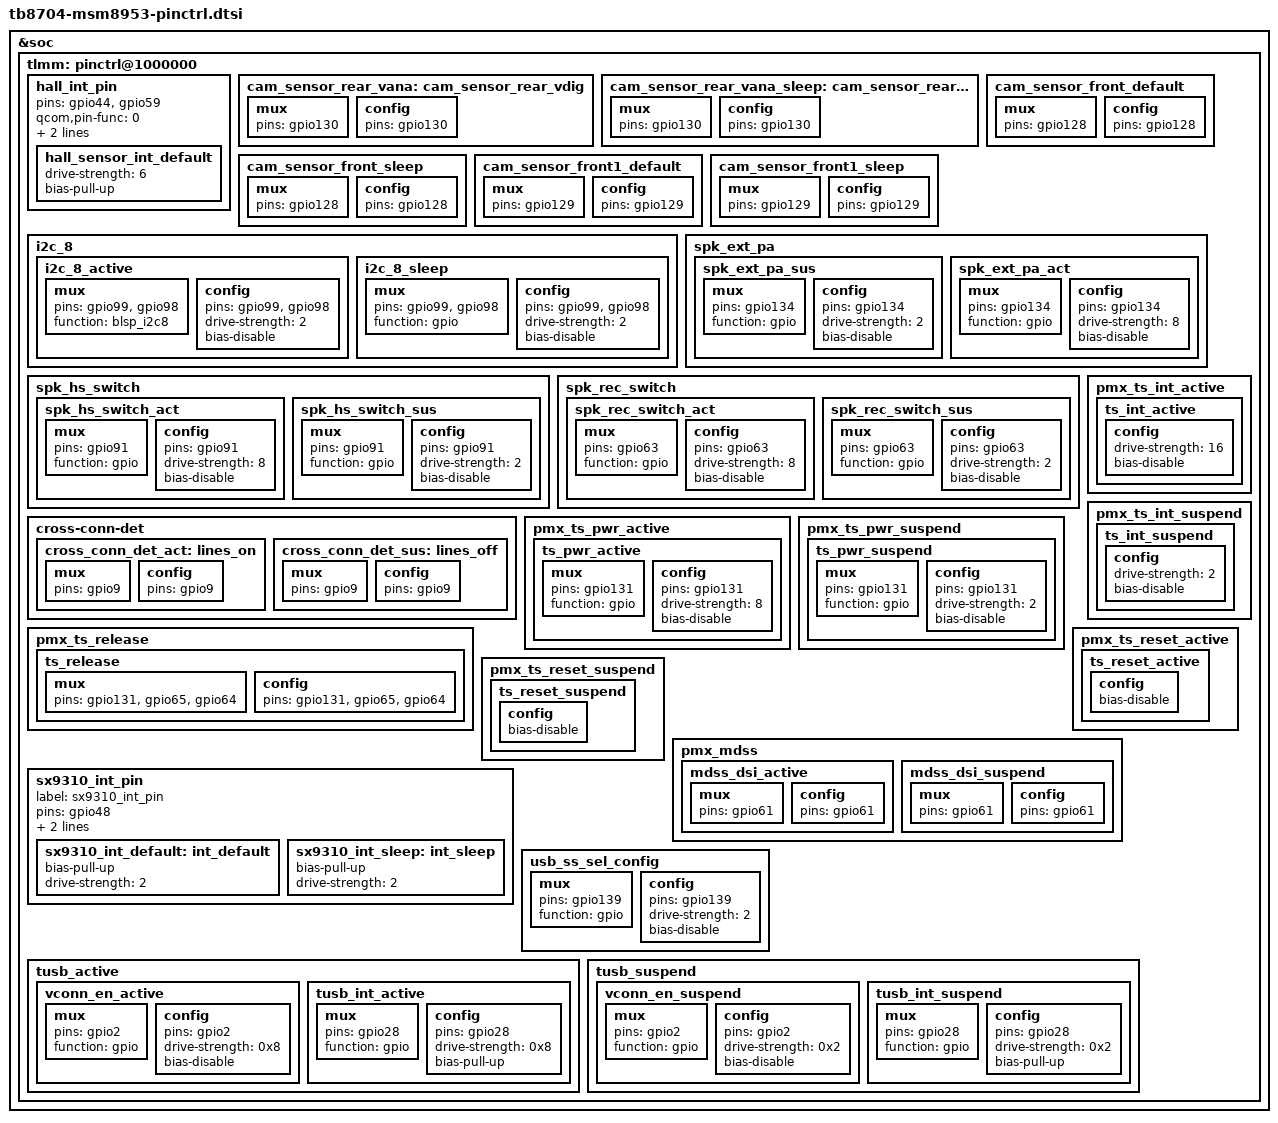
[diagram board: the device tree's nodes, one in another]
/*
 * Copyright (c) 2015-2016, The Linux Foundation. All rights reserved.
 *
 * This program is free software; you can redistribute it and/or modify
 * it under the terms of the GNU General Public License version 2 and
 * only version 2 as published by the Free Software Foundation.
 *
 * This program is distributed in the hope that it will be useful,
 * but WITHOUT ANY WARRANTY; without even the implied warranty of
 * MERCHANTABILITY or FITNESS FOR A PARTICULAR PURPOSE.  See the
 * GNU General Public License for more details.
 */

&soc {
	tlmm: pinctrl@1000000 {
		hall_int_pin {
			pins = "gpio44", "gpio59";
			qcom,pin-func = <0>;
			qcom,num-grp-pins = <2>;
			label = "hall_irq";
			hall_sensor_int_default: hall_sensor_int_default {
				drive-strength = <6>;
				bias-pull-up;
			};
		};

		cam_sensor_rear_vana: cam_sensor_rear_vdig {
			/* VDIG */
			mux {
				pins = "gpio130";
			};

			config {
				pins = "gpio130";
			};
		};

		cam_sensor_rear_vana_sleep: cam_sensor_rear_vdig_sleep {
			/* VDIG */
			mux {
				pins = "gpio130";
			};

			config {
				pins = "gpio130";
			};
		};


		cam_sensor_front_default: cam_sensor_front_default {
			/* RESET, STANDBY */
			mux {
				pins = "gpio128";
			};

			config {
				pins = "gpio128";
			};
		};

		cam_sensor_front_sleep: cam_sensor_front_sleep {
			/* RESET, STANDBY */
			mux {
				pins = "gpio128";
			};

			config {
				pins = "gpio128";
			};
		};


		cam_sensor_front1_default: cam_sensor_front1_default {
			/* RESET, STANDBY */
			mux {
				pins = "gpio129";
			};

			config {
				pins = "gpio129";
			};
		};

		cam_sensor_front1_sleep: cam_sensor_front1_sleep {
			/* RESET, STANDBY */
			mux {
				pins = "gpio129";
			};

			config {
				pins = "gpio129";
			};
		};

		i2c_8 {
			i2c_8_active: i2c_8_active {
				/* active state */
				mux {
					pins = "gpio99", "gpio98";
					function = "blsp_i2c8";
				};

				config {
					pins = "gpio99", "gpio98";
					drive-strength = <2>;
					bias-disable;
				};
			};

			i2c_8_sleep: i2c_8_sleep {
				/* suspended state */
				mux {
					pins = "gpio99", "gpio98";
					function = "gpio";
				};

				config {
					pins = "gpio99", "gpio98";
					drive-strength = <2>;
					bias-disable;
				};
			};
		};

		spk_ext_pa {
			spk_ext_pa_sus: spk_ext_pa_sus {
				mux {
					pins = "gpio134";
					function = "gpio";
				};
				config {
				    pins = "gpio134";
				    drive-strength = <2>;
				    //output-low;
				    //bias-pull-down;
				    bias-disable;
				};
			};
			spk_ext_pa_act: spk_ext_pa_act {
				mux {
					pins = "gpio134";
					function = "gpio";
				};
				config {
				    pins = "gpio134";
				    drive-strength = <8>;
				    bias-disable;
				};
			};
		};

		spk_hs_switch {
			spk_hs_switch_act: spk_hs_switch_act {
				mux {
					pins = "gpio91";
					function = "gpio";
				};
				config {
				    pins = "gpio91";
				    drive-strength = <8>;
				    bias-disable;
				    //output-high;
				};
			};
			spk_hs_switch_sus: spk_hs_switch_sus {
				mux {
					pins = "gpio91";
					function = "gpio";
				};
				config {
					pins = "gpio91";
					drive-strength = <2>;
					bias-disable;
				};
			};
		};
		
		spk_rec_switch {
			spk_rec_switch_act: spk_rec_switch_act {
				mux {
					pins = "gpio63";
					function = "gpio";
				};
				config {
			        pins = "gpio63";
					drive-strength = <8>;
					bias-disable;
					//output-high;
				};
			};
			spk_rec_switch_sus: spk_rec_switch_sus {
				mux {
					pins = "gpio63";
					function = "gpio";
				};
				config {
					pins = "gpio63";
					drive-strength = <2>;
					bias-disable;
				};
			};
		};

		cross-conn-det {
			cross_conn_det_act: lines_on {
				mux {
					pins = "gpio9";
				};

				config {
					pins = "gpio9";
				};
			};

			cross_conn_det_sus: lines_off {
				mux {
					pins = "gpio9";
				};

				config {
					pins = "gpio9";
				};
			};
		};


		/* add pingrp for touchscreen */
		pmx_ts_int_active {
			ts_int_active: ts_int_active {

				config {
					drive-strength = <16>;
					bias-disable;
					/delete-property/ bias-pull-up;
				};
			};
		};

		pmx_ts_int_suspend {
			ts_int_suspend: ts_int_suspend {

				config {
					drive-strength = <2>;
					bias-disable;
					/delete-property/ bias-pull-down;
				};
			};
		};

		pmx_ts_pwr_active {
			ts_pwr_active: ts_pwr_active {
				mux {
					pins = "gpio131";
					function = "gpio";
				};

				config {
					pins = "gpio131";
					drive-strength = <8>;
					bias-disable;
				};
			};
		};

		pmx_ts_pwr_suspend {
			ts_pwr_suspend: ts_pwr_suspend {
				mux {
					pins = "gpio131";
					function = "gpio";
				};

				config {
					pins = "gpio131";
					drive-strength = <2>;
					bias-disable;
				};
			};
		};

		pmx_ts_release {
			ts_release: ts_release {
				mux {
					pins = "gpio131", "gpio65", "gpio64";
				};
				
				config {
					pins = "gpio131", "gpio65", "gpio64";
				};
			};
		};
		pmx_ts_reset_active {
			ts_reset_active: ts_reset_active {
				config {
					bias-disable;
					/delete-property/ bias-pull-up;
				};
			};
		};

		pmx_ts_reset_suspend {
			ts_reset_suspend: ts_reset_suspend {
				config {
					bias-disable;
					/delete-property/ bias-pull-down;
				};
			};
		};
		pmx_mdss: pmx_mdss {
			mdss_dsi_active: mdss_dsi_active {
				mux {
					pins = "gpio61";
				};
			config {
					pins = "gpio61";
				};
			};

			mdss_dsi_suspend: mdss_dsi_suspend {
				mux {
					pins = "gpio61";
				};

				config {
					pins = "gpio61";
				};
			};
		};

		sx9310_int_pin: sx9310_int_pin {
				label = "sx9310_int_pin";
				pins = "gpio48";
				qcom,num-grp-pins = <0x1>;
				qcom,pin-func = <0x0>;

				sx9310_int_default: int_default {
					bias-pull-up;
					drive-strength = <2>;
				};

				sx9310_int_sleep: int_sleep {
					bias-pull-up;
					drive-strength = <2>;
				};
		};

		usb_ss_sel_config: usb_ss_sel_config {
			mux {
				pins = "gpio139";
				function = "gpio";
			};

			config {
				pins = "gpio139";
				drive-strength = <2>;
				bias-disable;
			};
		};
		tusb_active {

                                vconn_en_active: vconn_en_active {
                                        mux {
                                                pins = "gpio2";
                                                function = "gpio";
                                        };

                                        config {
                                                pins = "gpio2";
                                                drive-strength = <0x8>;
                                                bias-disable;
                                        };
                                };

                                tusb_int_active: tusb_int_active {
                                        mux {
                                                pins = "gpio28";
                                                function = "gpio";
                                        };

                                        config {
                                                pins = "gpio28";
                                                drive-strength = <0x8>;
                                                bias-pull-up;
                                        };
                                };
                };
                tusb_suspend {

                                vconn_en_suspend: vconn_en_suspend {
                                        mux {
                                                pins = "gpio2";
                                                function = "gpio";
                                        };

                                        config {
                                                pins = "gpio2";
                                                drive-strength = <0x2>;
                                                bias-disable;
                                        };
                                };

                                tusb_int_suspend: tusb_int_suspend {
                                        mux {
                                                pins = "gpio28";
                                                function = "gpio";
                                        };

                                        config {
                                                pins = "gpio28";
                                                drive-strength = <0x2>;
                                                bias-pull-up;
                                        };
                                };
                };

	};
};
